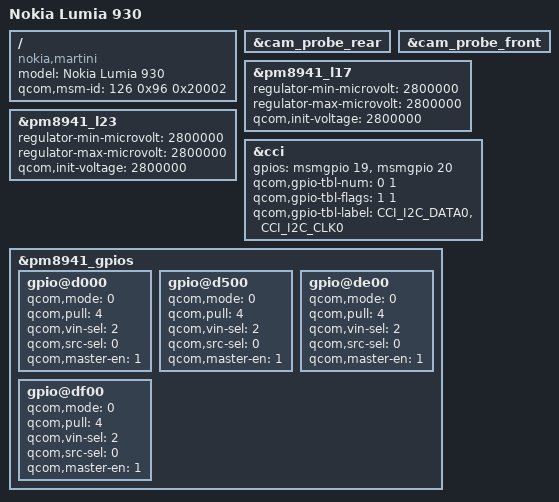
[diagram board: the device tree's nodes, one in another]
/*
 * Nokia Lumia 930 (martini) camera identification test DTB.
 *
 * Same board as msm8974-v2.2-martini.dts, with the read-only camera sensor
 * identification probe nodes enabled. Build it on its own and append it to
 * zImage in place of the normal DTB (see kit/camera/README). Nothing else
 * changes; the camera stays off until the probe is triggered through
 * /sys/kernel/debug/nokia_camprobe/scan.
 *
 * Copyright (c) 2026, Lorenzo Giannoccaro. GPLv2 only.
 */

/dts-v1/;

/include/ "msm8974-v2.2.dtsi"
/include/ "msm8974-martini/msm8974-martini.dtsi"
/include/ "msm8974-camera-sensor-lumia-probe.dtsi"

/ {
	model = "Nokia Lumia 930";
	compatible = "nokia,martini", "qcom,msm8974";
	qcom,msm-id = <126 0x96 0x20002>;
};

&cam_probe_rear {
	status = "ok";
};

&cam_probe_front {
	status = "ok";
};

/*
 * The PEP powers both camera modules at 2.8 V; the shared regulator table
 * pins L23 at 3.0 V and L17 at 2.85 V, which would refuse the request.
 * Nothing else on the 930 uses these two rails.
 */
&pm8941_l17 {
	regulator-min-microvolt = <2800000>;
	regulator-max-microvolt = <2800000>;
	qcom,init-voltage = <2800000>;
};

&pm8941_l23 {
	regulator-min-microvolt = <2800000>;
	regulator-max-microvolt = <2800000>;
	qcom,init-voltage = <2800000>;
};

/*
 * CCI master 1 is not used on the Lumias; leave GPIO 21/22 to the probe
 * (extra_high) to find out whether they enable a camera rail.
 */
&cci {
	gpios = <&msmgpio 19 0>,
		<&msmgpio 20 0>;
	qcom,gpio-tbl-num = <0 1>;
	qcom,gpio-tbl-flags = <1 1>;
	qcom,gpio-tbl-label = "CCI_I2C_DATA0",
			      "CCI_I2C_CLK0";
};

/*
 * PMIC GPIOs that Windows uses (not parked by \_SB.SDFR sleep) but no known
 * device claims: keep them inputs as the UEFI leaves them, only move their
 * supply to VIN2 (1.8 V, like the other 930 PMIC GPIOs) so the probe can
 * drive one high at 1.8 V (extra_high).
 */
&pm8941_gpios {
	gpio@d000 {	/* GPIO 17 */
		qcom,mode = <0>;
		qcom,pull = <4>;
		qcom,vin-sel = <2>;
		qcom,src-sel = <0>;
		qcom,master-en = <1>;
	};
	gpio@d500 {	/* GPIO 22 */
		qcom,mode = <0>;
		qcom,pull = <4>;
		qcom,vin-sel = <2>;
		qcom,src-sel = <0>;
		qcom,master-en = <1>;
	};
	gpio@de00 {	/* GPIO 31 */
		qcom,mode = <0>;
		qcom,pull = <4>;
		qcom,vin-sel = <2>;
		qcom,src-sel = <0>;
		qcom,master-en = <1>;
	};
	gpio@df00 {	/* GPIO 32 */
		qcom,mode = <0>;
		qcom,pull = <4>;
		qcom,vin-sel = <2>;
		qcom,src-sel = <0>;
		qcom,master-en = <1>;
	};
};
